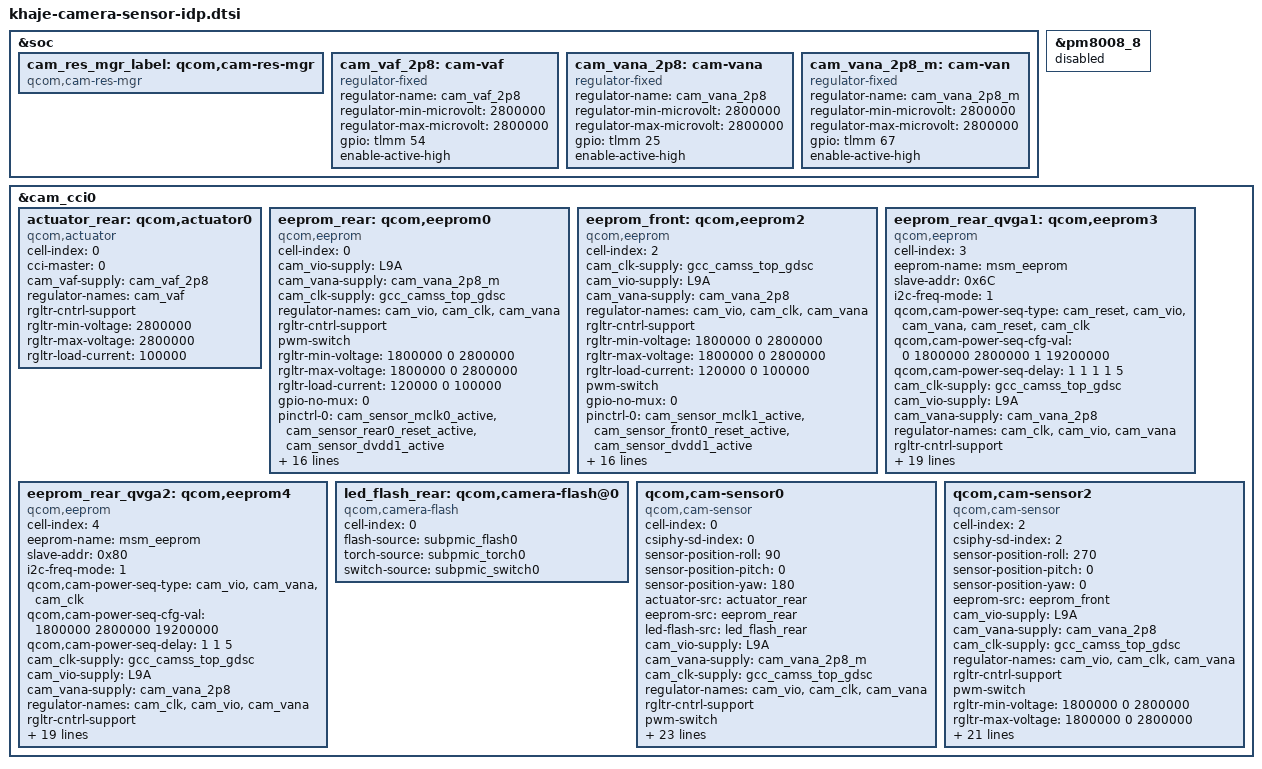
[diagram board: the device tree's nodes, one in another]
#include <dt-bindings/clock/qcom,gcc-khaje.h>
#include <dt-bindings/msm-camera.h>

&soc {
	cam_res_mgr_label: qcom,cam-res-mgr {
		compatible = "qcom,cam-res-mgr";
		status = "ok";
	};

	cam_vaf_2p8: cam-vaf {
		compatible = "regulator-fixed";
		regulator-name = "cam_vaf_2p8";
		regulator-min-microvolt = <2800000>;
		regulator-max-microvolt = <2800000>;
		gpio = <&tlmm 54 0>;
		enable-active-high;
		status = "okay";
	};

	cam_vana_2p8: cam-vana {
		compatible = "regulator-fixed";
		regulator-name = "cam_vana_2p8";
		regulator-min-microvolt = <2800000>;
		regulator-max-microvolt = <2800000>;
		gpio = <&tlmm 25 0>;
		enable-active-high;
		status = "okay";
	};

	cam_vana_2p8_m: cam-van {
		compatible = "regulator-fixed";
		regulator-name = "cam_vana_2p8_m";
		regulator-min-microvolt = <2800000>;
		regulator-max-microvolt = <2800000>;
		gpio = <&tlmm 67 0>;
		enable-active-high;
		status = "okay";
	};
};

&pm8008_8 {
    status = "disabled";
};

&cam_cci0 {
	actuator_rear: qcom,actuator0 {
		cell-index = <0>;
		compatible = "qcom,actuator";
		cci-master = <0>;
		cam_vaf-supply = <&cam_vaf_2p8>;
		regulator-names = "cam_vaf";
		rgltr-cntrl-support;
		rgltr-min-voltage = <2800000>;
		rgltr-max-voltage = <2800000>;
		rgltr-load-current = <100000>;
		status = "ok";
	};

	eeprom_rear: qcom,eeprom0 {
		cell-index = <0>;
		compatible = "qcom,eeprom";
		cam_vio-supply = <&L9A>;
		cam_vana-supply = <&cam_vana_2p8_m>;
		cam_clk-supply = <&gcc_camss_top_gdsc>;
		regulator-names = "cam_vio", "cam_clk", "cam_vana";
		rgltr-cntrl-support;
		pwm-switch;
		rgltr-min-voltage = <1800000 0 2800000>;
		rgltr-max-voltage = <1800000 0 2800000>;
		rgltr-load-current = <120000 0 100000>;
		gpio-no-mux = <0>;
		pinctrl-names = "cam_default", "cam_suspend";
		pinctrl-0 = <&cam_sensor_mclk0_active
			&cam_sensor_rear0_reset_active
			&cam_sensor_dvdd1_active>;
		pinctrl-1 = <&cam_sensor_mclk0_suspend
			&cam_sensor_rear0_reset_suspend
			&cam_sensor_dvdd1_suspend>;
		gpios = <&tlmm 20 0>,
			<&tlmm 18 0>,
			<&tlmm 27 0>,//dvdd enable
			<&tlmm 58 0>;//dvdd 1.05V
		gpio-reset = <1>;
		gpio-custom2  = <2>;
		gpio-custom1  = <3>;
		gpio-req-tbl-num = <0 1 2 3>;
		gpio-req-tbl-flags = <1 0 0 1>;
		gpio-req-tbl-label = "CAMIF_MCLK0",
			"CAM_RESET0",
			"CAM_DVDD0",
			"CAM_CUSTOM0";
		sensor-mode = <0>;
		cci-master = <0>;
		status = "ok";
		clocks = <&gcc GCC_CAMSS_MCLK0_CLK >;
		clock-names = "cam_clk";
		clock-cntl-level = "turbo";
		clock-rates = <19200000>;
	};

	eeprom_front: qcom,eeprom2 {
		cell-index = <2>;
		compatible = "qcom,eeprom";
		cam_clk-supply = <&gcc_camss_top_gdsc>;
		cam_vio-supply = <&L9A>;
		cam_vana-supply = <&cam_vana_2p8>;
		regulator-names = "cam_vio","cam_clk","cam_vana";
		rgltr-cntrl-support;
		rgltr-min-voltage = <1800000 0 2800000>;
		rgltr-max-voltage = <1800000 0 2800000>;
		rgltr-load-current = <120000 0 100000>;
		pwm-switch;
		gpio-no-mux = <0>;
		pinctrl-names = "cam_default", "cam_suspend";
		pinctrl-0 = <&cam_sensor_mclk1_active
			&cam_sensor_front0_reset_active
			&cam_sensor_dvdd1_active>;
		pinctrl-1 = <&cam_sensor_mclk1_suspend
			&cam_sensor_front0_reset_suspend
			&cam_sensor_dvdd1_suspend>;
		gpios = <&tlmm 21 0>,//mclk
			<&tlmm 19 0>,//rst
			<&tlmm 27 0>,//dvdd enable
			<&tlmm 58 0>;//dvdd 1.2V
		gpio-reset = <1>;
		gpio-custom2 = <2>;
		gpio-custom1 = <3>;
		gpio-req-tbl-num = <0 1 2 3>;
		gpio-req-tbl-flags = <1 0 0 1>;
		gpio-req-tbl-label = "CAMIF_MCLK1",
			"CAM_RESET1",
			"CAM_DVDD1",
			"CAM_CUSTOM1";
		sensor-mode = <0>;
		cci-master = <1>;
		status = "ok";
		clocks = <&gcc GCC_CAMSS_MCLK1_CLK>;
		clock-names = "cam_clk";
		clock-cntl-level = "turbo";
		clock-rates = <19200000>;
	};

	eeprom_rear_qvga1: qcom,eeprom3 {
		cell-index = <3>;
		compatible = "qcom,eeprom";
		eeprom-name = "msm_eeprom";
		slave-addr = <0x6C>;
		i2c-freq-mode = <1>;
		qcom,cam-power-seq-type = "cam_reset", "cam_vio", "cam_vana", "cam_reset", "cam_clk";
		qcom,cam-power-seq-cfg-val = <0 1800000 2800000 1 19200000>;
		qcom,cam-power-seq-delay = <1 1 1 1 5>;
		cam_clk-supply = <&gcc_camss_top_gdsc>;
		cam_vio-supply = <&L9A>;
		cam_vana-supply = <&cam_vana_2p8>;
		regulator-names = "cam_clk","cam_vio","cam_vana";
		rgltr-cntrl-support;
		rgltr-min-voltage = <0 1800000 2800000>;
		rgltr-max-voltage = <0 1800000 2800000>;
		rgltr-load-current = <0 1800000 2800000>;
		pwm-switch;
		gpio-no-mux = <0>;
		pinctrl-names = "cam_default", "cam_suspend";
		pinctrl-0 = <&cam_sensor_mclk3_active
			&cam_sensor_qvga_reset_active>;
		pinctrl-1 = <&cam_sensor_mclk3_suspend
			&cam_sensor_qvga_reset_suspend>;
		gpios = <&tlmm 28 0>,
			<&tlmm 31 0>;
		gpio-reset = <1>;
		gpio-req-tbl-num = <0 1>;
		gpio-req-tbl-flags = <1 0>;
		gpio-req-tbl-label = "CAMIF_MCLK3",
			"CAM_RESET3";
		sensor-mode = <0>;
		cci-master = <1>;
		status = "ok";
		clocks = <&gcc GCC_CAMSS_MCLK3_CLK>;
		clock-names = "cam_clk";
		clock-cntl-level = "turbo";
		clock-rates = <19200000>;
	};

	eeprom_rear_qvga2: qcom,eeprom4 {
		cell-index = <4>;
		compatible = "qcom,eeprom";
		eeprom-name = "msm_eeprom";
		slave-addr = <0x80>;
		i2c-freq-mode = <1>;
		qcom,cam-power-seq-type = "cam_vio", "cam_vana", "cam_clk";
		qcom,cam-power-seq-cfg-val = <1800000 2800000 19200000>;
		qcom,cam-power-seq-delay = <1 1 5>;
		cam_clk-supply = <&gcc_camss_top_gdsc>;
		cam_vio-supply = <&L9A>;
		cam_vana-supply = <&cam_vana_2p8>;
		regulator-names = "cam_clk","cam_vio","cam_vana";
		rgltr-cntrl-support;
		rgltr-min-voltage = <0 1800000 2800000>;
		rgltr-max-voltage = <0 1800000 2800000>;
		rgltr-load-current = <0 1800000 2800000>;
		pwm-switch;
		gpio-no-mux = <0>;
		pinctrl-names = "cam_default", "cam_suspend";
		pinctrl-0 = <&cam_sensor_mclk3_active
			&cam_sensor_qvga_reset_active>;
		pinctrl-1 = <&cam_sensor_mclk3_suspend
			&cam_sensor_qvga_reset_suspend>;
		gpios = <&tlmm 28 0>,
			<&tlmm 31 0>;
		gpio-reset = <1>;
		gpio-req-tbl-num = <0 1>;
		gpio-req-tbl-flags = <1 0>;
		gpio-req-tbl-label = "CAMIF_MCLK3",
			"CAM_RESET3";
		sensor-mode = <0>;
		cci-master = <1>;
		status = "ok";
		clocks = <&gcc GCC_CAMSS_MCLK3_CLK>;
		clock-names = "cam_clk";
		clock-cntl-level = "turbo";
		clock-rates = <19200000>;
	};

	led_flash_rear: qcom,camera-flash@0 {
		cell-index = <0>;
		compatible = "qcom,camera-flash";
		flash-source = <&subpmic_flash0>;
		torch-source = <&subpmic_torch0>;
		switch-source = <&subpmic_switch0>;
		status = "ok";
	};

	/* Rear*/
	qcom,cam-sensor0 {
		cell-index = <0>;
		compatible = "qcom,cam-sensor";
		csiphy-sd-index = <0>;
		sensor-position-roll = <90>;
		sensor-position-pitch = <0>;
		sensor-position-yaw = <180>;
		actuator-src = <&actuator_rear>;
		eeprom-src = <&eeprom_rear>;
		led-flash-src = <&led_flash_rear>;
		cam_vio-supply = <&L9A>;
		cam_vana-supply = <&cam_vana_2p8_m>;
		cam_clk-supply = <&gcc_camss_top_gdsc>;
		regulator-names = "cam_vio", "cam_clk", "cam_vana";
		rgltr-cntrl-support;
		pwm-switch;
		rgltr-min-voltage = <1800000 0 2800000>;
		rgltr-max-voltage = <1800000 0 2800000>;
		rgltr-load-current = <120000 0 100000>;
		gpio-no-mux = <0>;
		pinctrl-names = "cam_default", "cam_suspend";
		pinctrl-0 = <&cam_sensor_mclk0_active
			&cam_sensor_rear0_reset_active
			&cam_sensor_dvdd1_active>;
		pinctrl-1 = <&cam_sensor_mclk0_suspend
			&cam_sensor_rear0_reset_suspend
			&cam_sensor_dvdd1_suspend>;
		gpios = <&tlmm 20 0>,
			<&tlmm 18 0>,
			<&tlmm 27 0>,//dvdd enable
			<&tlmm 58 0>;//dvdd 1.05V
		gpio-reset = <1>;
		gpio-custom2  = <2>;
		gpio-custom1  = <3>;
		gpio-req-tbl-num = <0 1 2 3>;
		gpio-req-tbl-flags = <1 0 0 1>;
		gpio-req-tbl-label = "CAMIF_MCLK0",
			"CAM_RESET0",
			"CAM_DVDD0",
			"CAM_CUSTOM0";
		sensor-mode = <0>;
		cci-master = <0>;
		status = "ok";
		clocks = <&gcc GCC_CAMSS_MCLK0_CLK>;
		clock-names = "cam_clk";
		clock-cntl-level = "turbo";
		clock-rates = <19200000>;
    };

	/*Front*/
	qcom,cam-sensor2 {
		cell-index = <2>;
		compatible = "qcom,cam-sensor";
		csiphy-sd-index = <2>;
		sensor-position-roll = <270>;
		sensor-position-pitch = <0>;
		sensor-position-yaw = <0>;
		eeprom-src = <&eeprom_front>;
		cam_vio-supply = <&L9A>;
		cam_vana-supply = <&cam_vana_2p8>;
		cam_clk-supply = <&gcc_camss_top_gdsc>;
		regulator-names = "cam_vio","cam_clk", "cam_vana";
		rgltr-cntrl-support;
		pwm-switch;
		rgltr-min-voltage = <1800000 0 2800000>;
		rgltr-max-voltage = <1800000 0 2800000>;
		rgltr-load-current = <120000 0 100000>;
		gpio-no-mux = <0>;
		pinctrl-names = "cam_default", "cam_suspend";
		pinctrl-0 = <&cam_sensor_mclk1_active
			&cam_sensor_front0_reset_active
			&cam_sensor_dvdd1_active>;
		pinctrl-1 = <&cam_sensor_mclk1_suspend
			&cam_sensor_front0_reset_suspend
			&cam_sensor_dvdd1_suspend>;
		gpios = <&tlmm 21 0>,//mclk
			<&tlmm 19 0>,//rst
			<&tlmm 27 0>,//dvdd enable
			<&tlmm 58 0>;//dvdd 1.2V
		gpio-reset = <1>;
		gpio-custom2 = <2>;
		gpio-custom1 = <3>;
		gpio-req-tbl-num = <0 1 2 3>;
		gpio-req-tbl-flags = <1 0 0 1>;
		gpio-req-tbl-label = "CAMIF_MCLK1",
			"CAM_RESET1",
			"CAM_DVDD1",
			"CAM_CUSTOM1";
		sensor-mode = <0>;
		cci-master = <1>;
		status = "ok";
		clocks = <&gcc GCC_CAMSS_MCLK1_CLK>;
		clock-names = "cam_clk";
		clock-cntl-level = "turbo";
		clock-rates = <19200000>;
	};
};
